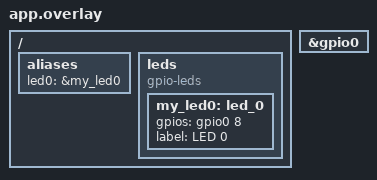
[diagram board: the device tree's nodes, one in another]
/ {
    aliases {
        led0 = &my_led0;
    };
    leds {
        compatible = "gpio-leds";
        my_led0: led_0 {
            gpios = <&gpio0 8 GPIO_ACTIVE_HIGH>;
            label = "LED 0";
        };
    };
};

&gpio0 {
    status = "okay";
};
